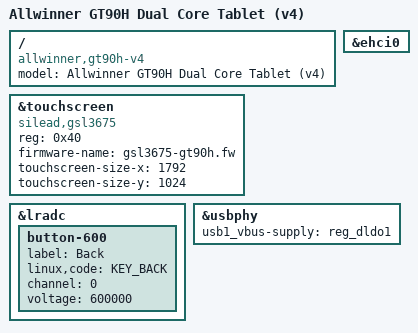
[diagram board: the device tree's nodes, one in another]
/dts-v1/;
#include "sun8i-a23.dtsi"
#include "sun8i-reference-design-tablet.dtsi"
/ {
	model = "Allwinner GT90H Dual Core Tablet (v4)";
	compatible = "allwinner,gt90h-v4", "allwinner,sun8i-a23";
};
&ehci0 {
	status = "okay";
};
&touchscreen {
	reg = <0x40>;
	compatible = "silead,gsl3675";
	firmware-name = "gsl3675-gt90h.fw";
	touchscreen-size-x = <1792>;
	touchscreen-size-y = <1024>;
	status = "okay";
};
&lradc {
	button-600 {
		label = "Back";
		linux,code = <KEY_BACK>;
		channel = <0>;
		voltage = <600000>;
	};
};
&usbphy {
	usb1_vbus-supply = <&reg_dldo1>;
};
